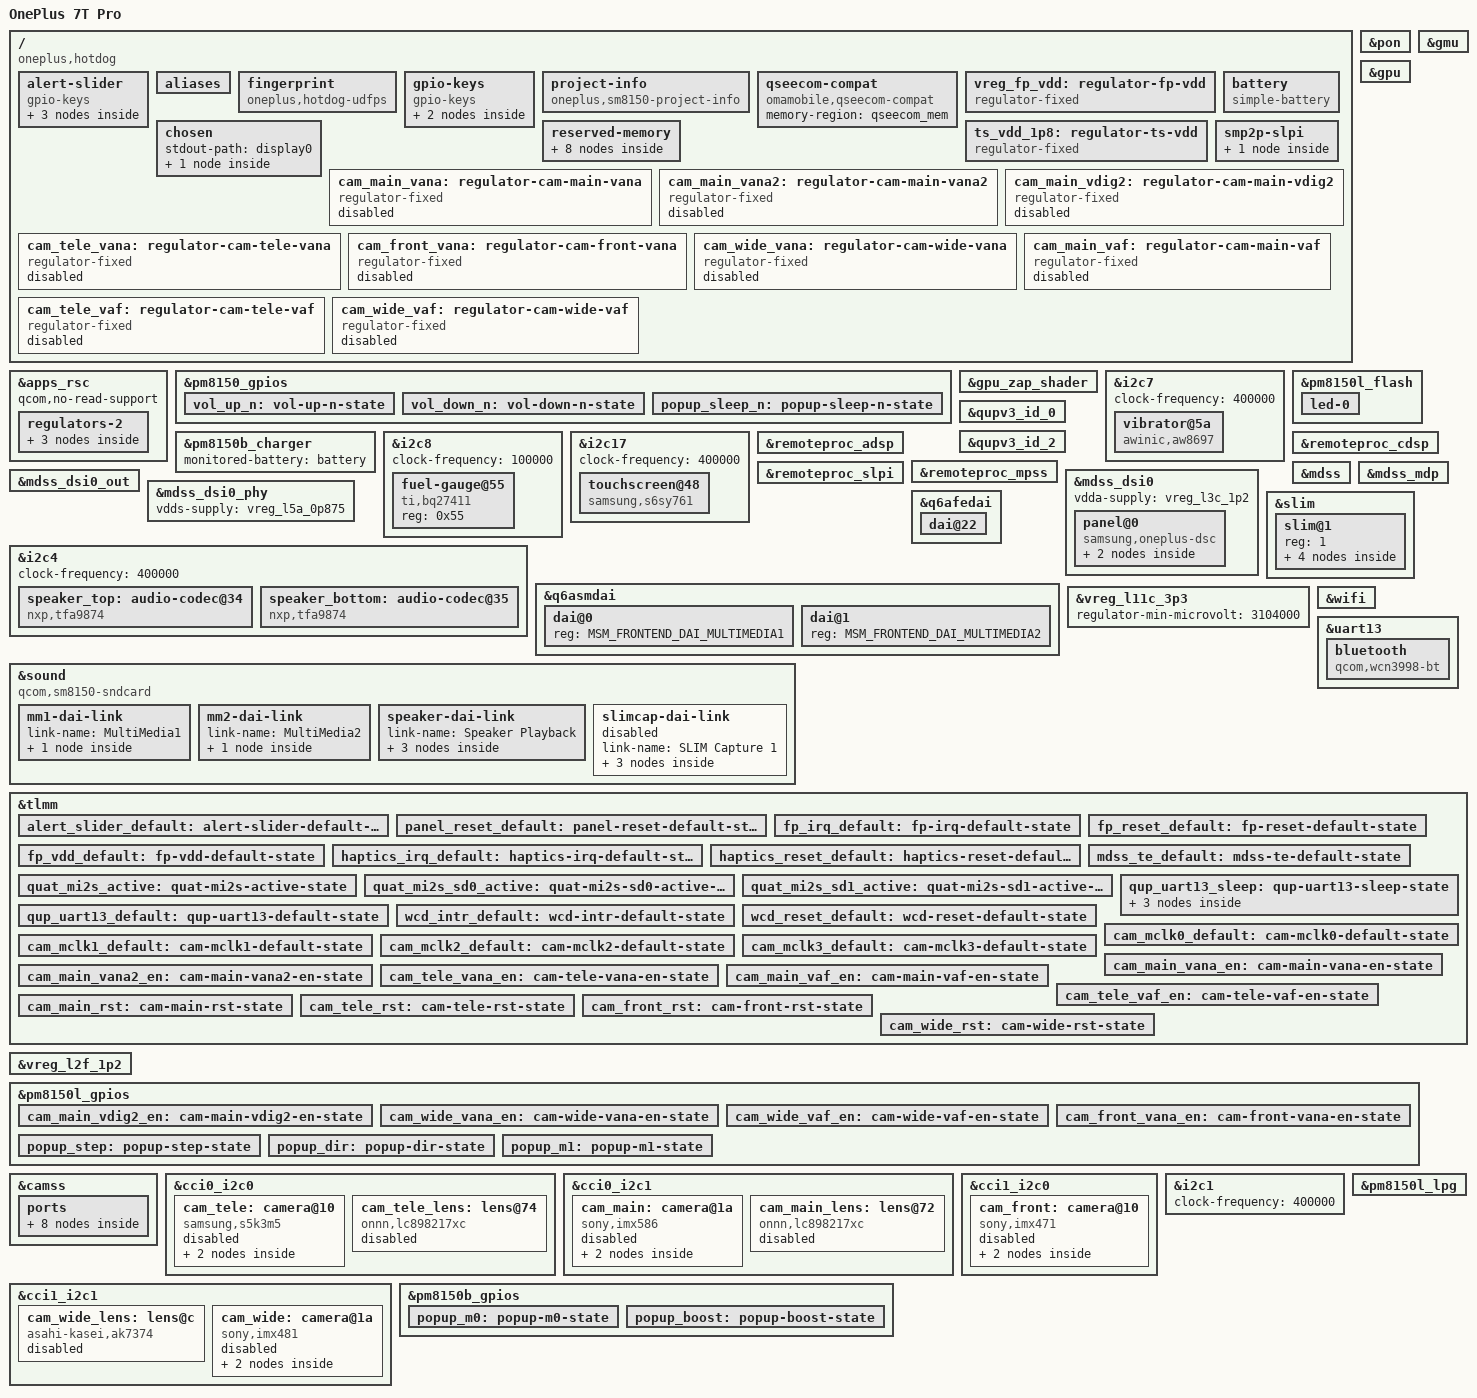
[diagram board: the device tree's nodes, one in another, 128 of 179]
// SPDX-License-Identifier: BSD-3-Clause
/*
 * Devicetree for the OnePlus 7T Pro (hotdog, project 19801).
 *
 * The board is the OnePlus 7 Pro's (guacamole): OnePlus's downstream
 * kernel builds both from the same sm8150-oem.dtsi (panel, S6SY761 touch
 * on QUP SE17, UFS, USB) and differs only in charger and battery
 * properties, which mainline doesn't describe. ABL picks the appended DTB
 * by qcom,msm-id: given a DTB without one, it answered `fastboot boot`
 * with OKAY and stayed in fastboot (Android 12 ABL). The phone's ABL
 * reports SoC 339 (SM8150); downstream also builds the board on SM8150P
 * (361), so both are listed at v2. board-id <8 0> is downstream hotdog's.
 *
 * Based on sm8150-oneplus-guacamole.dts:
 * Copyright (c) 2021, Caleb Connolly <caleb@connolly.tech>
 * Reserved regions from OnePlus's downstream sm8150.dtsi and sm8150-oem.dtsi.
 *
 * Enabled: the panel as ABL left it (simple-framebuffer), UFS, USB
 * peripheral, touch (S6SY761), the fuel gauge (BQ27411), the power and
 * volume keys and the alert slider.
 */

/dts-v1/;

#include <dt-bindings/arm/qcom,ids.h>
#include <dt-bindings/regulator/qcom,rpmh-regulator.h>
#include <dt-bindings/gpio/gpio.h>
#include <dt-bindings/interrupt-controller/irq.h>
#include <dt-bindings/leds/common.h>
#include <dt-bindings/sound/qcom,q6asm.h>
#include <dt-bindings/media/video-interfaces.h>
#include "sm8150-oneplus-common.dtsi"

/* Redone below, with guard pages, where this phone's modem expects it. */
/delete-node/ &rmtfs_mem;

/ {
	model = "OnePlus 7T Pro";
	compatible = "oneplus,hotdog", "qcom,sm8150";

	qcom,msm-id = <QCOM_ID_SM8150 0x20000>, <361 0x20000>; /* SM8150, SM8150P v2 */
	qcom,board-id = <8 0>;

	/*
	 * The three-position alert slider: one line per position, from the
	 * vendor tri-state-key node (gpio_key1 = TLMM 27, gpio_key2 = TLMM 134,
	 * gpio_key3 = TLMM 125, no internal bias). The order follows the
	 * OnePlus 6's slider in sdm845-oneplus-common.dtsi, whose vendor node
	 * lists its lines the same way (key1 bottom, key3 top). Reported as
	 * ABS_SND_PROFILE, the event the input core defines for such switches.
	 * All three lines are in the PDC's wake map, so a move wakes the phone
	 * from suspend and the new profile applies at once.
	 */
	alert-slider {
		compatible = "gpio-keys";
		label = "Alert slider";

		pinctrl-0 = <&alert_slider_default>;
		pinctrl-names = "default";

		switch-top {
			label = "Silent";
			linux,input-type = <EV_ABS>;
			linux,code = <ABS_SND_PROFILE>;
			linux,input-value = <SND_PROFILE_SILENT>;
			gpios = <&tlmm 125 GPIO_ACTIVE_LOW>;
			linux,can-disable;
			wakeup-source;
		};

		switch-middle {
			label = "Vibrate";
			linux,input-type = <EV_ABS>;
			linux,code = <ABS_SND_PROFILE>;
			linux,input-value = <SND_PROFILE_VIBRATE>;
			gpios = <&tlmm 134 GPIO_ACTIVE_LOW>;
			linux,can-disable;
			wakeup-source;
		};

		switch-bottom {
			label = "Ring";
			linux,input-type = <EV_ABS>;
			linux,code = <ABS_SND_PROFILE>;
			linux,input-value = <SND_PROFILE_RING>;
			gpios = <&tlmm 27 GPIO_ACTIVE_LOW>;
			linux,can-disable;
			wakeup-source;
		};
	};

	aliases {
		display0 = &framebuffer0;
		hsuart0 = &uart13;
	};

	/*
	 * Goodix optical sensor under the panel (stock goodix_fp node). Its SPI
	 * bus (QUP0 SE3, gpio144-147) belongs to the Goodix trusted application
	 * in QSEE; Linux drives its supply switch (gpio101), reset (gpio131) and
	 * interrupt (gpio118), and keeps the bus's pins and clocks on for QSEE,
	 * as stock's enabled qupv3_se3_spi node with no child did. spi3 itself
	 * stays disabled: Linux never drives that serial engine.
	 */
	fingerprint {
		compatible = "oneplus,hotdog-udfps";
		interrupts-extended = <&tlmm 118 IRQ_TYPE_EDGE_RISING>;
		reset-gpios = <&tlmm 131 GPIO_ACTIVE_LOW>;
		vdd-supply = <&vreg_fp_vdd>;

		clocks = <&gcc GCC_QUPV3_WRAP0_S3_CLK>,
			 <&gcc GCC_QUPV3_WRAP_0_M_AHB_CLK>,
			 <&gcc GCC_QUPV3_WRAP_0_S_AHB_CLK>;
		clock-names = "se", "m-ahb", "s-ahb";

		pinctrl-0 = <&fp_irq_default &fp_reset_default &qup_spi3_default>;
		pinctrl-names = "default";
	};

	/*
	 * The volume keys are PM8150 GPIO6 (up) and GPIO7 (down), active low with
	 * the PMIC's pull-up at the 1.8 V vin-1, as in the vendor gpio_keys node.
	 * Sampled on the phone on 2026-11-15: GPIO6 low only while Volume Up was
	 * held, GPIO7 only while Volume Down was. The vendor tree also gives
	 * PON RESIN KEY_VOLUMEDOWN; it stays disabled (as pm8150.dtsi leaves
	 * it) so one press can't report twice.
	 */
	gpio-keys {
		compatible = "gpio-keys";
		label = "Volume keys";
		autorepeat;

		pinctrl-0 = <&vol_up_n>, <&vol_down_n>;
		pinctrl-names = "default";

		key-vol-up {
			label = "Volume Up";
			linux,code = <KEY_VOLUMEUP>;
			gpios = <&pm8150_gpios 6 GPIO_ACTIVE_LOW>;
			debounce-interval = <15>;
			linux,can-disable;
			wakeup-source;
		};

		key-vol-down {
			label = "Volume Down";
			linux,code = <KEY_VOLUMEDOWN>;
			gpios = <&pm8150_gpios 7 GPIO_ACTIVE_LOW>;
			debounce-interval = <15>;
			linux,can-disable;
			wakeup-source;
		};
	};

	/* Sets the RF test cable state in SMEM for the modem (rf_v3 = no cable). */
	project-info {
		compatible = "oneplus,sm8150-project-info";
	};

	/*
	 * Downstream's /dev/qseecom for the vendor fingerprint HAL, with its
	 * shared buffers in the qseecom carve-out. Its module refuses every
	 * trusted application and listener that its allow-lists (module
	 * parameters, set by the device package) do not name.
	 */
	qseecom-compat {
		compatible = "omamobile,qseecom-compat";
		memory-region = <&qseecom_mem>;
	};

	/*
	 * The sensor's supply switch (stock fp_vdd_init / fp_vdd_dis_init). It
	 * stays off until goodix-fp's device is opened.
	 */
	vreg_fp_vdd: regulator-fp-vdd {
		compatible = "regulator-fixed";
		regulator-name = "fp_vdd";
		gpio = <&tlmm 101 GPIO_ACTIVE_HIGH>;
		enable-active-high;

		pinctrl-0 = <&fp_vdd_default>;
		pinctrl-names = "default";
	};

	/*
	 * 4085mAh typ. (gauge design capacity 4040mAh). Float voltage 4.35V,
	 * the value OnePlus's bootloader leaves in the charger (FLOAT_VOLTAGE_CFG
	 * 0x4b); downstream runs 4.365-4.39V by temperature region. The DCP
	 * input current stays below downstream's 1.8A usb-icl.
	 */
	battery: battery {
		compatible = "simple-battery";
		charge-full-design-microamp-hours = <4040000>;
		voltage-min-design-microvolt = <3400000>;
		voltage-max-design-microvolt = <4350000>;
		constant-charge-current-max-microamp = <1500000>;
	};

	chosen {
		#address-cells = <2>;
		#size-cells = <2>;
		ranges;
		stdout-path = "display0";

		/* The panel as ABL left it (cont_splash_region, 1440x3120). */
		framebuffer0: framebuffer@9c000000 {
			compatible = "simple-framebuffer";
			reg = <0 0x9c000000 0 (1440 * 3120 * 4)>;
			width = <1440>;
			height = <3120>;
			stride = <(1440 * 4)>;
			format = "a8r8g8b8";
		};
	};

	/*
	 * The touchscreen's 1.8 V: a load switch from S4A whose enable, GPIO 119,
	 * is held high by its pull-up (tp_1v8_active), as downstream leaves it.
	 */
	ts_vdd_1p8: regulator-ts-vdd {
		compatible = "regulator-fixed";
		regulator-name = "ts_vdd_1p8";
		regulator-min-microvolt = <1800000>;
		regulator-max-microvolt = <1800000>;
		regulator-always-on;
		regulator-boot-on;
		vin-supply = <&vreg_s4a_1p8>;
	};

	/*
	 * Downstream regions mainline's sm8150.dtsi leaves as System RAM.
	 * Firmware owns some of them at runtime, so keep Linux out of all.
	 */
	reserved-memory {
		/*
		 * Downstream xbl_aop_mem is 0x85e00000-0x85f40000. Mainline's
		 * xbl_mem, aop_mem and aop_cmd_db cover all of it except this gap.
		 */
		xbl_aop_gap_mem: memory@85e40000 {
			reg = <0 0x85e40000 0 0xc0000>;
			no-map;
		};

		/* The tail of downstream removed_regions, past mainline tz_mem. */
		removed_mem: memory@89b00000 {
			reg = <0 0x89b00000 0 0x1c00000>;
			no-map;
		};

		/* Downstream cont_splash_region: ABL's display buffers. */
		splash_mem: memory@9c000000 {
			reg = <0 0x9c000000 0 0x2400000>;
			no-map;
		};

		/* OnePlus's bootloader_log_mem. */
		bootloader_log_mem: memory@9fff7000 {
			reg = <0 0x9fff7000 0 0x9000>;
			no-map;
		};

		cdsp_sec_mem: memory@a4c00000 {
			reg = <0 0xa4c00000 0 0x3c00000>;
			no-map;
		};

		/*
		 * Stock's ramoops region. ramoops_probe() rounds each zone size
		 * down to a power of two and gives the dmesg records what is
		 * left, so the layout is: six 0x40000 dmesg records at +0,
		 * the console at +0x180000, pmsg at +0x1c0000 and ftrace at
		 * +0x3c0000. OnePlus's downstream kernel keeps a 0x1000
		 * devinfo zone in the same region, and its console starts
		 * 0x1000 lower (the crash-dump table names it KMSG, at
		 * 0xa997f008), so the two kernels' zones don't line up.
		 */
		ramoops@a9800000 {
			compatible = "ramoops";
			reg = <0 0xa9800000 0 0x400000>;
			record-size = <0x40000>;
			console-size = <0x40000>;
			ftrace-size = <0x40000>;
			pmsg-size = <0x200000>;
			ecc-size = <0>;
		};

		/* OnePlus's param_mem and mtp_mem. */
		param_mem: memory@ac200000 {
			reg = <0 0xac200000 0 0xc00000>;
			no-map;
		};

		/*
		 * Downstream allocates rmtfs at runtime (qcom,rmtfs_sharedmem,
		 * 2 MiB with qcom,guard-memory). On the OnePlus 7 Pro it always
		 * ends up at 0xf2901000 (sm8150-oneplus-common.dtsi). Same
		 * region here, plus the 4 KiB guard page on each side so no
		 * Linux allocation sits next to the XPU-protected range.
		 */
		rmtfs_mem: memory@f2900000 {
			compatible = "qcom,rmtfs-mem";
			reg = <0 0xf2900000 0 0x202000>;
			no-map;

			qcom,client-id = <1>;
			qcom,vmid = <QCOM_SCM_VMID_MSS_MSA>;
			qcom,use-guard-pages;
		};
	};

	/*
	 * The SLPI's sensors PD (its CHRE) takes a fatal error unless the APPS
	 * side has a "sleepstate" outbound smp2p entry, as downstream's
	 * smp2p-sleepstate driver provides. Nothing drives it yet.
	 */
	smp2p-slpi {
		sleepstate {
			qcom,entry-name = "sleepstate";
			#qcom,smem-state-cells = <1>;
		};
	};
};

/*
 * This board's apps RSC never answers an RPMh read: refuse them rather
 * than lose both active TCSes to two reads that never complete.
 */
&apps_rsc {
	qcom,no-read-support;
};

/*
 * `reboot bootloader` / `reboot recovery`: the same PON spare codes as
 * downstream's qpnp_pon_set_restart_reason() (gen2: reason << 1), which ABL reads.
 */
&pon {
	mode-bootloader = <0x2>;
	mode-recovery = <0x1>;
};

&pm8150_gpios {
	vol_up_n: vol-up-n-state {
		pins = "gpio6";
		function = "normal";
		power-source = <1>;
		bias-pull-up;
		input-enable;
	};

	vol_down_n: vol-down-n-state {
		pins = "gpio7";
		function = "normal";
		power-source = <1>;
		bias-pull-up;
		input-enable;
	};
};

&gmu {
	status = "okay";
};

&gpu {
	status = "okay";
};

/* From the phone's own vendor partition (/vendor/firmware/a640_zap.*). */
&gpu_zap_shader {
	firmware-name = "qcom/sm8150/oneplus/hotdog/a640_zap.mbn";
};

/*
 * Downstream qupv3_se7_i2c: the Awinic AW8697 LRA haptics driver (stock
 * aw8697_haptic@5A, reset on GPIO 116, interrupt on GPIO 24). The chip
 * measured the actuator at 175-176 Hz; OnePlus ships waveform sets for
 * 166 to 174 Hz.
 */
&i2c7 {
	clock-frequency = <400000>;
	status = "okay";

	vibrator@5a {
		compatible = "awinic,aw8697";
		reg = <0x5a>;
		interrupts-extended = <&tlmm 24 IRQ_TYPE_EDGE_FALLING>;
		reset-gpios = <&tlmm 116 GPIO_ACTIVE_LOW>;
		pinctrl-0 = <&haptics_irq_default &haptics_reset_default>;
		pinctrl-names = "default";
		awinic,f0-hz = <170>;
	};
};

/*
 * The rear dual-tone flash: two LEDs on the PM8150L flash module's channels
 * 1 and 2, which stock always drives together (torch_0 + torch_1 behind
 * switch_2). One torch-only LED over both, capped at stock's torch current
 * (300 mA per channel, current-ma of torch_0/torch_1; the module allows
 * 500). No flash-max-microamp: nothing here fires the flash strobe.
 * Disabled until the bring-up overlay has run (CAMERA-PLAN, T1-T2).
 */
&pm8150l_flash {
	led-0 {
		function = LED_FUNCTION_TORCH;
		color = <LED_COLOR_ID_WHITE>;
		led-sources = <1>, <2>;
		led-max-microamp = <600000>;
	};
};

/*
 * Plain USB charging (SDP 0.5A, CDP/DCP 1.5A input; fast charge current 1.95A).
 * Hardware JEITA stays as the bootloader configured it. No Warp/Dash.
 */
&pm8150b_charger {
	monitored-battery = <&battery>;
	status = "okay";
};

/* Downstream qupv3_se8_i2c: fuel gauge and OnePlus's fast-charge MCU. */
&i2c8 {
	clock-frequency = <100000>;
	status = "okay";

	/*
	 * Downstream calls it bq27541, but its driver also detects a BQ27411
	 * (device type 0x0421) and the classic bq27541 register map reads
	 * garbage on this phone.
	 */
	fuel-gauge@55 {
		compatible = "ti,bq27411";
		reg = <0x55>;
	};
};

&qupv3_id_0 {
	status = "okay";
};

&qupv3_id_2 {
	status = "okay";
};

&i2c17 {
	clock-frequency = <400000>;
	status = "okay";

	/*
	 * Downstream hotdog: 3.0 V from L17A for the analog side, 1.8 V switched
	 * by GPIO 119 (tp_1v8_active), reset GPIO 54 held by tp_rst_active.
	 */
	touchscreen@48 {
		compatible = "samsung,s6sy761";
		reg = <0x48>;
		interrupt-parent = <&tlmm>;
		interrupts = <122 IRQ_TYPE_LEVEL_LOW>;
		avdd-supply = <&vreg_l17a_3p0>;
		vdd-supply = <&ts_vdd_1p8>;

		touchscreen-size-x = <1440>;
		touchscreen-size-y = <3120>;
		samsung,ear-detect;

		pinctrl-names = "default";
		pinctrl-0 = <&tp_irq_active &tp_rst_active &tp_1v8_active>;
	};
};

/*
 * Remote processors, squashed .mbn from the phone's modem partition. A missing
 * file just leaves the remoteproc offline. The modem doesn't boot by itself
 * (auto_boot off): rmtfs starts it once it serves the EFS partitions.
 * The ELF images are relocatable and each one spans its whole region
 * (adsp 0x1e00000, modem 0x9600000, cdsp/slpi 0x1400000).
 */
&remoteproc_adsp {
	firmware-name = "qcom/sm8150/oneplus/hotdog/adsp.mbn";
	status = "okay";
};

&remoteproc_cdsp {
	firmware-name = "qcom/sm8150/oneplus/hotdog/cdsp.mbn";
	status = "okay";
};

&remoteproc_mpss {
	firmware-name = "qcom/sm8150/oneplus/hotdog/modem.mbn";
	status = "okay";
};

/*
 * The SLPI runs the sensors (Snapdragon Sensor Core: light, proximity,
 * accelerometer, compass). Its sensor_process PD reads its registry and
 * configs from Linux over FastRPC (hexagonrpcd, started by the device
 * package when /dev/fastrpc-sdsp appears); without that it stalls and its
 * watchdog restarts the SLPI about 40 s after boot.
 */
&remoteproc_slpi {
	firmware-name = "qcom/sm8150/oneplus/hotdog/slpi.mbn";
	status = "okay";
};

/*
 * Display: Samsung 1440x3120 AMOLED, command mode, DSC with two encoders on
 * one 4-lane DSI link (downstream topology <2 2 1>). Pins and supply from
 * downstream dsi_samsung_oneplus_dsc_cmd: reset GPIO 6, TE GPIO 8, vddio
 * from L14A; the other rails are switched by the panel itself.
 */
&mdss {
	status = "okay";
};

&mdss_mdp {
	status = "okay";
};

&mdss_dsi0 {
	vdda-supply = <&vreg_l3c_1p2>;
	status = "okay";

	panel@0 {
		compatible = "samsung,oneplus-dsc";
		reg = <0>;

		vddio-supply = <&vreg_l14a_1p8>;
		reset-gpios = <&tlmm 6 GPIO_ACTIVE_LOW>;

		pinctrl-names = "default";
		pinctrl-0 = <&panel_reset_default &mdss_te_default>;

		port {
			panel_in: endpoint {
				remote-endpoint = <&mdss_dsi0_out>;
			};
		};
	};
};

&mdss_dsi0_out {
	data-lanes = <0 1 2 3>;
	remote-endpoint = <&panel_in>;
};

&mdss_dsi0_phy {
	vdds-supply = <&vreg_l5a_0p875>;
	status = "okay";
};

/*
 * Speakers: two NXP TFA9874 amps on QUP SE4 I2C (downstream qupv3_se4_i2c,
 * reset GPIOs 37 and 100, active high), fed by the ADSP over quaternary MI2S
 * (SCK GPIO 137, WS 138; audio on SD1, GPIO 140, as downstream's dai_mi2s3
 * rx-lines; the amps' sense data would come back on SD0). 0x34 is the
 * earpiece at the top (the only one with a receiver profile), playing the
 * left I2S channel; 0x35 is the bottom speaker, playing the right one.
 *
 * nxp,init-bitfields replay the device and "speaker" profile settings of
 * OnePlus's tfa98xx.cnt (NXP bitfield IDs: 32-bit slots, 64 BCLK per frame,
 * slot assignment, DC-DC booster, gains). Speaker protection ran on the ADSP
 * under Android (NXP's TFADSP); it doesn't here.
 */
&i2c4 {
	clock-frequency = <400000>;
	status = "okay";

	speaker_top: audio-codec@34 {
		compatible = "nxp,tfa9874";
		reg = <0x34>;
		reset-gpios = <&tlmm 37 GPIO_ACTIVE_HIGH>;
		#sound-dai-cells = <0>;
		sound-name-prefix = "Top";
		nxp,init-bitfields = <0x20c3 2>, <0x2144 31>, <0x2224 31>, <0x2330 1>,
				     <0x2340 0>, <0x6802 3>, <0x0401 1>, <0x2310 1>,
				     <0x6163 4>, <0x6123 15>, <0x6831 1>, <0x6851 2>,
				     <0x0255 22>, <0x5257 190>, <0x5350 1>, <0x64e1 2>,
				     <0x5690 0>, <0x6f02 5>, <0x6f72 1>, <0x7071 3>,
				     <0x7430 1>, <0x7494 8>, <0x75f0 1>, <0x74f0 0>,
				     <0x8001 0>, <0x8305 25>, <0x8364 30>, <0x8453 4>,
				     <0x5150 0>, <0x5844 1>, <0x6f50 1>, <0x8510 1>,
				     <0x8530 0>, <0x8540 0>, <0x8801 2>, <0x8440 0>,
				     <0xc4d0 0>, <0xb050 0>, <0x7444 10>, <0x7534 5>,
				     <0x7584 16>, <0x7635 30>, <0x7695 63>, <0x0040 1>,
				     <0x0240 0>, <0x62e1 0>, <0x2603 0>, <0x2643 1>,
				     <0x26c3 0>, <0x2703 1>, <0x7033 11>;
	};

	speaker_bottom: audio-codec@35 {
		compatible = "nxp,tfa9874";
		reg = <0x35>;
		reset-gpios = <&tlmm 100 GPIO_ACTIVE_HIGH>;
		#sound-dai-cells = <0>;
		sound-name-prefix = "Bottom";
		nxp,init-bitfields = <0x20c3 2>, <0x2144 31>, <0x2224 31>, <0x2330 1>,
				     <0x2340 0>, <0x6802 3>, <0x0401 1>, <0x2310 1>,
				     <0x6163 4>, <0x6123 15>, <0x6831 1>, <0x6851 2>,
				     <0x0255 22>, <0x5257 190>, <0x5350 1>, <0x64e1 2>,
				     <0x5690 0>, <0x6f02 5>, <0x6f72 1>, <0x7071 3>,
				     <0x7430 1>, <0x7494 8>, <0x75f0 1>, <0x74f0 0>,
				     <0x8001 0>, <0x8305 25>, <0x8364 30>, <0x8453 4>,
				     <0x5150 0>, <0x5844 1>, <0x6f50 1>, <0x8510 1>,
				     <0x8530 0>, <0x8540 0>, <0x8801 2>, <0x8440 0>,
				     <0xc4d0 0>, <0xb050 0>, <0x7444 10>, <0x7534 5>,
				     <0x7584 16>, <0x7635 30>, <0x7695 63>, <0x0040 1>,
				     <0x0240 0>, <0x62e1 0>, <0x2603 1>, <0x2643 0>,
				     <0x26c3 1>, <0x2703 0>, <0x7033 10>;
	};
};

&q6afedai {
	dai@22 {
		reg = <QUATERNARY_MI2S_RX>;
		qcom,sd-lines = <1>;
	};
};

&q6asmdai {
	dai@0 {
		reg = <MSM_FRONTEND_DAI_MULTIMEDIA1>;
	};

	dai@1 {
		reg = <MSM_FRONTEND_DAI_MULTIMEDIA2>;
	};
};

&sound {
	compatible = "qcom,sm8150-sndcard";
	model = "OnePlus 7T Pro";
	pinctrl-names = "default";
	pinctrl-0 = <&quat_mi2s_active &quat_mi2s_sd0_active &quat_mi2s_sd1_active>;

	mm1-dai-link {
		link-name = "MultiMedia1";

		cpu {
			sound-dai = <&q6asmdai MSM_FRONTEND_DAI_MULTIMEDIA1>;
		};
	};

	mm2-dai-link {
		link-name = "MultiMedia2";

		cpu {
			sound-dai = <&q6asmdai MSM_FRONTEND_DAI_MULTIMEDIA2>;
		};
	};

	speaker-dai-link {
		link-name = "Speaker Playback";

		cpu {
			sound-dai = <&q6afedai QUATERNARY_MI2S_RX>;
		};

		platform {
			sound-dai = <&q6routing>;
		};

		codec {
			sound-dai = <&speaker_top>, <&speaker_bottom>;
		};
	};

	/*
	 * Microphones: WCD9340 AIF1_CAP on SLIMbus 0 TX. Disabled until the
	 * mic bring-up overlay (omarchy-mobile device/hotdog/overlays/mic.dtso)
	 * enables it with the SLIMbus controller and adds the card's routes:
	 * a card linked to a codec that never probes would also lose the
	 * speakers.
	 */
	slimcap-dai-link {
		link-name = "SLIM Capture 1";
		status = "disabled";

		cpu {
			sound-dai = <&q6afedai SLIMBUS_0_TX>;
		};

		platform {
			sound-dai = <&q6routing>;
		};

		codec {
			sound-dai = <&wcd9340 1>; /* AIF1_CAP */
		};
	};
};

/*
 * Microphones: a WCD9340 (Tavil) codec on SLIMbus, as OnePlus's downstream
 * sm8150 tavil_codec (stock dtbo, project 19801): reset GPIO 143, its
 * interrupt on GPIO 123, MCLK from LN_BB_CLK2 (downstream clock_audio_lnbb,
 * RPMh clock 2), 1.8 V supplies from S4A and the micbias LDO's input from
 * PM8150L BoB (downstream cdc-vdd-3v3 at 3.3 V). Micbias levels as stock:
 * 2.7 V on MICBIAS1, 2 and 4, 1.8 V on MICBIAS3. Three analog microphones
 * (stock mixer_paths_tavil.xml): AMIC4 is the voice mic ("handset-mic"),
 * AMIC3 the recording mic ("handset-mic-rec") and AMIC1 the third; AMIC2 is
 * the USB-C headset mic. The phone has no WSA speakers, so the codec's
 * SoundWire master stays off.
 *
 * The SLIMbus controller stays disabled here; the mic bring-up overlay
 * enables it.
 */
&slim {
	slim@1 {
		reg = <1>;
		#address-cells = <2>;
		#size-cells = <0>;

		wcd9340_ifd: ifd@0,0 {
			compatible = "slim217,250";
			reg = <0 0>;
		};

		wcd9340: codec@1,0 {
			compatible = "slim217,250";
			reg = <1 0>;
			slim-ifc-dev = <&wcd9340_ifd>;

			#sound-dai-cells = <1>;

			interrupts-extended = <&tlmm 123 IRQ_TYPE_LEVEL_HIGH>;
			interrupt-controller;
			#interrupt-cells = <1>;

			clock-names = "extclk";
			clocks = <&rpmhcc RPMH_LN_BB_CLK2>;

			#clock-cells = <0>;
			clock-frequency = <9600000>;
			clock-output-names = "mclk";

			pinctrl-0 = <&wcd_intr_default &wcd_reset_default>;
			pinctrl-names = "default";

			reset-gpios = <&tlmm 143 GPIO_ACTIVE_HIGH>;

			vdd-buck-supply = <&vreg_s4a_1p8>;
			vdd-buck-sido-supply = <&vreg_s4a_1p8>;
			vdd-tx-supply = <&vreg_s4a_1p8>;
			vdd-rx-supply = <&vreg_s4a_1p8>;
			vdd-io-supply = <&vreg_s4a_1p8>;
			vdd-micbias-supply = <&vreg_bob>;

			qcom,micbias1-microvolt = <2700000>;
			qcom,micbias2-microvolt = <2700000>;
			qcom,micbias3-microvolt = <1800000>;
			qcom,micbias4-microvolt = <2700000>;

			#address-cells = <1>;
			#size-cells = <1>;

			wcdgpio: gpio-controller@42 {
				compatible = "qcom,wcd9340-gpio";
				gpio-controller;
				#gpio-cells = <2>;
				reg = <0x42 0x2>;
			};

			swm: soundwire@c85 {
				compatible = "qcom,soundwire-v1.3.0";
				reg = <0xc85 0x40>;
				interrupts-extended = <&wcd9340 20>;

				qcom,dout-ports = <6>;
				qcom,din-ports = <2>;
				qcom,ports-sinterval-low =
					/bits/ 8 <0x07 0x1f 0x3f 0x07 0x1f 0x3f 0x0f 0x0f>;
				qcom,ports-offset1 =
					/bits/ 8 <0x01 0x02 0x0c 0x06 0x12 0x0d 0x07 0x0a>;
				qcom,ports-offset2 =
					/bits/ 8 <0x00 0x00 0x1f 0x00 0x00 0x1f 0x00 0x00>;

				#sound-dai-cells = <1>;
				clocks = <&wcd9340>;
				clock-names = "iface";
				#address-cells = <2>;
				#size-cells = <0>;

				status = "disabled";
			};
		};
	};
};

/*
 * WCN3990 rails from downstream's icnss node: cx-mx L1A (0.752 V), xo L7A
 * (1.8 V), rfa L2C (1.304 V), ch0 L11C (3.104-3.312 V; downstream BT asks for
 * 3.312 V on the same LDO). No ch1. MSA is wlan_mem, the same 0x180000 at
 * 0x8bc00000 as downstream's qcom,wlan-msa-fixed-region. Its firmware
 * (wlanmdsp.mbn) is loaded by the modem over tqftpserv; the board data
 * is looked up as variant oneplus_hotdog in ath10k's board-2.bin.
 */
&vreg_l11c_3p3 {
	regulator-min-microvolt = <3104000>;
};

&wifi {
	vdd-0.8-cx-mx-supply = <&vreg_l1a_0p75>;
	vdd-1.8-xo-supply = <&vreg_l7a_1p8>;
	vdd-1.3-rfa-supply = <&vreg_l2c_1p3>;
	vdd-3.3-ch0-supply = <&vreg_l11c_3p3>;

	qcom,calibration-variant = "oneplus_hotdog";

	status = "okay";
};

/*
 * WCN3990 Bluetooth on QUP SE13 as a 4-wire UART (downstream
 * qupv3_se13_4uart, wake IRQ on RX GPIO 46), powered from the same rails as
 * Wi-Fi. Firmware is stock's bluetooth_a image: crbtfw21.tlv and the NVM
 * picked by board ID (crnv21.bXX, else crnv21.bin), as Android does.
 */
&uart13 {
	/delete-property/ interrupts;
	interrupts-extended = <&intc GIC_SPI 585 IRQ_TYPE_LEVEL_HIGH>,
			      <&tlmm 46 IRQ_TYPE_EDGE_FALLING>;

	pinctrl-names = "default", "sleep";
	pinctrl-0 = <&qup_uart13_default>;
	pinctrl-1 = <&qup_uart13_sleep>;

	status = "okay";

	bluetooth: bluetooth {
		compatible = "qcom,wcn3998-bt";
		vddio-supply = <&vreg_l1a_0p75>;
		vddxo-supply = <&vreg_l7a_1p8>;
		vddrf-supply = <&vreg_l2c_1p3>;
		vddch0-supply = <&vreg_l11c_3p3>;
		max-speed = <3200000>;
		firmware-name = "crnv21", "crbtfw21.tlv";
	};
};

&tlmm {
	alert_slider_default: alert-slider-default-state {
		pins = "gpio27", "gpio125", "gpio134";
		function = "gpio";
		drive-strength = <2>;
		bias-disable;
	};

	panel_reset_default: panel-reset-default-state {
		pins = "gpio6";
		function = "gpio";
		drive-strength = <8>;
		bias-disable;
	};

	/* Fingerprint pins as stock's fp_irq_init, fp_reset_init, fp_vdd_*. */
	fp_irq_default: fp-irq-default-state {
		pins = "gpio118";
		function = "gpio";
		drive-strength = <2>;
		bias-disable;
		output-disable;
	};

	fp_reset_default: fp-reset-default-state {
		pins = "gpio131";
		function = "gpio";
		drive-strength = <8>;
		bias-pull-up;
	};

	/* Stock pulls down while off; the regulator drives it while on. */
	fp_vdd_default: fp-vdd-default-state {
		pins = "gpio101";
		function = "gpio";
		drive-strength = <8>;
		bias-pull-down;
	};

	/* Haptics pins as stock's aw_irq and aw_reset (whose names are swapped). */
	haptics_irq_default: haptics-irq-default-state {
		pins = "gpio24";
		function = "gpio";
		drive-strength = <2>;
		bias-disable;
		output-disable;
	};

	haptics_reset_default: haptics-reset-default-state {
		pins = "gpio116";
		function = "gpio";
		drive-strength = <2>;
		bias-disable;
	};

	mdss_te_default: mdss-te-default-state {
		pins = "gpio8";
		function = "mdp_vsync";
		drive-strength = <2>;
		bias-pull-down;
	};

	/* Pin settings from downstream's quat_mi2s*_active states. */
	quat_mi2s_active: quat-mi2s-active-state {
		pins = "gpio137", "gpio138";
		function = "qua_mi2s";
		drive-strength = <8>;
		bias-disable;
		output-high;
	};

	quat_mi2s_sd0_active: quat-mi2s-sd0-active-state {
		pins = "gpio139";
		function = "qua_mi2s";
		drive-strength = <8>;
		bias-disable;
	};

	quat_mi2s_sd1_active: quat-mi2s-sd1-active-state {
		pins = "gpio140";
		function = "qua_mi2s";
		drive-strength = <8>;
		bias-disable;
	};

	qup_uart13_default: qup-uart13-default-state {
		pins = "gpio43", "gpio44", "gpio45", "gpio46";
		function = "qup13";
		drive-strength = <2>;
		bias-disable;
	};

	/* Pulls from downstream's qupv3_se13 sleep states. */
	qup_uart13_sleep: qup-uart13-sleep-state {
		pinmux {
			pins = "gpio43", "gpio44", "gpio45", "gpio46";
			function = "gpio";
		};

		pinconf-cts-rts {
			pins = "gpio43", "gpio44";
			bias-pull-down;
		};

		pinconf-tx-rx {
			pins = "gpio45", "gpio46";
			bias-pull-up;
		};
	};

	/* Stock's wcd_intr_default. */
	wcd_intr_default: wcd-intr-default-state {
		pins = "gpio123";
		function = "gpio";
		drive-strength = <2>;
		bias-pull-down;
	};

	/* Stock's cdc_reset_active; the driver drives the level. */
	wcd_reset_default: wcd-reset-default-state {
		pins = "gpio143";
		function = "gpio";
		drive-strength = <8>;
		bias-pull-down;
	};
};

/*
 * Cameras (CAMERA-PLAN.md). Everything below stays disabled; the plan's
 * overlays enable it one step at a time. Wiring from the vendor device tree
 * (dtbo entry 18, "MTP 19801", OnePlus's fragment on cam_cci0) and the
 * camera module files of OxygenOS 10.0.14:
 *
 *   camera     sensor  CCI     addr  CSIPHY          MCLK          XCLR
 *   rear main  IMX586  0 / m1  0x1a  1, C-PHY 3 trio 1, 19.2 MHz  gpio30
 *   telephoto  S5K3M5  0 / m0  0x10  0, D-PHY 4 lane 0, 24 MHz *  gpio28
 *   front      IMX471  1 / m0  0x10  2, D-PHY 4 lane 2, 19.2 MHz  gpio12
 *   ultrawide  IMX481  1 / m1  0x1a  3, D-PHY 4 lane 3, 19.2 MHz  gpio23
 *
 *   main:  vana gpio11, vana2 gpio29, vdig L1F 1.104 V, vdig2 PM8150L gpio1
 *   tele:  vana gpio148, vdig L2F 1.056 V
 *   front: vana PM8150L gpio12, vdig L3F 1.056 V
 *   wide:  vana PM8150L gpio2, vdig L4F 1.056 V
 *
 * All share vio (L1C, 1.8 V). The vana and vana2/vdig2 rails are load
 * switches the vendor tree drives as GPIOs, fed from BoB; their output
 * voltage is not described anywhere we can read. Stock runs the S5K3M5 at
 * 19.2 MHz; the mainline driver's tables are written for 24 MHz (*), which
 * the camera clock controller gives exactly. The OIS controllers and EEPROMs
 * are left out.
 *
 * Focus actuators (voice coils), from the same sources: each has its own
 * load switch from BoB (vendor "cam_vaf", 3.3 V), on gpio25 (main), gpio35
 * (tele) and PM8150L gpio4 (wide). Main and tele are one dual module, and
 * which chips it has depends on its maker: SEMCO's has LC898217XCs at 0x72
 * (main) and 0x74 (tele), O-film's AK7374s at 0x2d and 0x74. The nodes
 * below describe the SEMCO module; for an O-film one, the main lens is an
 * asahi-kasei,ak7374 at 0x2d and the tele lens an asahi-kasei,ak7374 at
 * 0x74. The ultrawide has an AK7374 at 0x0c either way. All three take
 * 10-bit positions. The lenses stay disabled, so the sensors' lens-focus
 * links are ignored, until a bring-up overlay enables them with their
 * switches.
 * Rotation is the vendor's sensor-position-roll; orientation its yaw.
 */
/ {
	cam_main_vana: regulator-cam-main-vana {
		compatible = "regulator-fixed";
		regulator-name = "cam_main_vana";
		gpio = <&tlmm 11 GPIO_ACTIVE_HIGH>;
		enable-active-high;
		vin-supply = <&vreg_bob>;
		pinctrl-0 = <&cam_main_vana_en>;
		pinctrl-names = "default";
		status = "disabled";
	};

	cam_main_vana2: regulator-cam-main-vana2 {
		compatible = "regulator-fixed";
		regulator-name = "cam_main_vana2";
		gpio = <&tlmm 29 GPIO_ACTIVE_HIGH>;
		enable-active-high;
		vin-supply = <&vreg_bob>;
		pinctrl-0 = <&cam_main_vana2_en>;
		pinctrl-names = "default";
		status = "disabled";
	};

	cam_main_vdig2: regulator-cam-main-vdig2 {
		compatible = "regulator-fixed";
		regulator-name = "cam_main_vdig2";
		gpio = <&pm8150l_gpios 1 GPIO_ACTIVE_HIGH>;
		enable-active-high;
		vin-supply = <&vreg_bob>;
		pinctrl-0 = <&cam_main_vdig2_en>;
		pinctrl-names = "default";
		status = "disabled";
	};

	cam_tele_vana: regulator-cam-tele-vana {
		compatible = "regulator-fixed";
		regulator-name = "cam_tele_vana";
		gpio = <&tlmm 148 GPIO_ACTIVE_HIGH>;
		enable-active-high;
		vin-supply = <&vreg_bob>;
		pinctrl-0 = <&cam_tele_vana_en>;
		pinctrl-names = "default";
		status = "disabled";
	};

	cam_front_vana: regulator-cam-front-vana {
		compatible = "regulator-fixed";
		regulator-name = "cam_front_vana";
		gpio = <&pm8150l_gpios 12 GPIO_ACTIVE_HIGH>;
		enable-active-high;
		vin-supply = <&vreg_bob>;
		pinctrl-0 = <&cam_front_vana_en>;
		pinctrl-names = "default";
		status = "disabled";
	};

	cam_wide_vana: regulator-cam-wide-vana {
		compatible = "regulator-fixed";
		regulator-name = "cam_wide_vana";
		gpio = <&pm8150l_gpios 2 GPIO_ACTIVE_HIGH>;
		enable-active-high;
		vin-supply = <&vreg_bob>;
		pinctrl-0 = <&cam_wide_vana_en>;
		pinctrl-names = "default";
		status = "disabled";
	};

	cam_main_vaf: regulator-cam-main-vaf {
		compatible = "regulator-fixed";
		regulator-name = "cam_main_vaf";
		gpio = <&tlmm 25 GPIO_ACTIVE_HIGH>;
		enable-active-high;
		vin-supply = <&vreg_bob>;
		pinctrl-0 = <&cam_main_vaf_en>;
		pinctrl-names = "default";
		status = "disabled";
	};

	cam_tele_vaf: regulator-cam-tele-vaf {
		compatible = "regulator-fixed";
		regulator-name = "cam_tele_vaf";
		gpio = <&tlmm 35 GPIO_ACTIVE_HIGH>;
		enable-active-high;
		vin-supply = <&vreg_bob>;
		pinctrl-0 = <&cam_tele_vaf_en>;
		pinctrl-names = "default";
		status = "disabled";
	};

	cam_wide_vaf: regulator-cam-wide-vaf {
		compatible = "regulator-fixed";
		regulator-name = "cam_wide_vaf";
		gpio = <&pm8150l_gpios 4 GPIO_ACTIVE_HIGH>;
		enable-active-high;
		vin-supply = <&vreg_bob>;
		pinctrl-0 = <&cam_wide_vaf_en>;
		pinctrl-names = "default";
		status = "disabled";
	};
};

&apps_rsc {
	regulators-2 {
		vreg_l1f_1p104: ldo1 {
			regulator-min-microvolt = <1104000>;
			regulator-max-microvolt = <1104000>;
			regulator-initial-mode = <RPMH_REGULATOR_MODE_HPM>;
		};

		vreg_l3f_1p056: ldo3 {
			regulator-min-microvolt = <1056000>;
			regulator-max-microvolt = <1056000>;
			regulator-initial-mode = <RPMH_REGULATOR_MODE_HPM>;
		};

		vreg_l4f_1p056: ldo4 {
			regulator-min-microvolt = <1056000>;
			regulator-max-microvolt = <1056000>;
			regulator-initial-mode = <RPMH_REGULATOR_MODE_HPM>;
		};
	};
};

/* The telephoto's digital core: 1.056 V on this board, not the MTP's 1.2 V. */
&vreg_l2f_1p2 {
	regulator-min-microvolt = <1056000>;
	regulator-max-microvolt = <1056000>;
};

&pm8150l_gpios {
	cam_main_vdig2_en: cam-main-vdig2-en-state {
		pins = "gpio1";
		function = "normal";
		power-source = <0>;
		bias-disable;
		output-low;
	};

	cam_wide_vana_en: cam-wide-vana-en-state {
		pins = "gpio2";
		function = "normal";
		power-source = <0>;
		bias-disable;
		output-low;
	};

	cam_wide_vaf_en: cam-wide-vaf-en-state {
		pins = "gpio4";
		function = "normal";
		power-source = <0>;
		bias-disable;
		output-low;
	};

	cam_front_vana_en: cam-front-vana-en-state {
		pins = "gpio12";
		function = "normal";
		power-source = <0>;
		bias-disable;
		output-low;
	};
};

&tlmm {
	cam_mclk0_default: cam-mclk0-default-state {
		pins = "gpio13";
		function = "cam_mclk";
		drive-strength = <2>;
		bias-disable;
	};

	cam_mclk1_default: cam-mclk1-default-state {
		pins = "gpio14";
		function = "cam_mclk";
		drive-strength = <2>;
		bias-disable;
	};

	cam_mclk2_default: cam-mclk2-default-state {
		pins = "gpio15";
		function = "cam_mclk";
		drive-strength = <2>;
		bias-disable;
	};

	cam_mclk3_default: cam-mclk3-default-state {
		pins = "gpio16";
		function = "cam_mclk";
		drive-strength = <2>;
		bias-disable;
	};

	cam_main_vana_en: cam-main-vana-en-state {
		pins = "gpio11";
		function = "gpio";
		drive-strength = <2>;
		bias-disable;
	};

	cam_main_vana2_en: cam-main-vana2-en-state {
		pins = "gpio29";
		function = "gpio";
		drive-strength = <2>;
		bias-disable;
	};

	cam_tele_vana_en: cam-tele-vana-en-state {
		pins = "gpio148";
		function = "gpio";
		drive-strength = <2>;
		bias-disable;
	};

	cam_main_vaf_en: cam-main-vaf-en-state {
		pins = "gpio25";
		function = "gpio";
		drive-strength = <2>;
		bias-disable;
	};

	cam_tele_vaf_en: cam-tele-vaf-en-state {
		pins = "gpio35";
		function = "gpio";
		drive-strength = <2>;
		bias-disable;
	};

	cam_main_rst: cam-main-rst-state {
		pins = "gpio30";
		function = "gpio";
		drive-strength = <2>;
		bias-disable;
	};

	cam_tele_rst: cam-tele-rst-state {
		pins = "gpio28";
		function = "gpio";
		drive-strength = <2>;
		bias-disable;
	};

	cam_front_rst: cam-front-rst-state {
		pins = "gpio12";
		function = "gpio";
		drive-strength = <2>;
		bias-disable;
	};

	cam_wide_rst: cam-wide-rst-state {
		pins = "gpio23";
		function = "gpio";
		drive-strength = <2>;
		bias-disable;
	};
};

&camss {
	vdda-phy-supply = <&vreg_l5a_0p875>;
	vdda-pll-supply = <&vreg_l3c_1p2>;

	ports {
		port@0 {
			camss_csiphy0_ep: endpoint {
				clock-lanes = <7>;
				data-lanes = <0 1 2 3>;
				remote-endpoint = <&cam_tele_ep>;
			};
		};

		port@1 {
			camss_csiphy1_ep: endpoint {
				bus-type = <MEDIA_BUS_TYPE_CSI2_CPHY>;
				clock-lanes = <7>;
				data-lanes = <0 1 2>;
				remote-endpoint = <&cam_main_ep>;
			};
		};

		port@2 {
			camss_csiphy2_ep: endpoint {
				clock-lanes = <7>;
				data-lanes = <0 1 2 3>;
				remote-endpoint = <&cam_front_ep>;
			};
		};

		port@3 {
			camss_csiphy3_ep: endpoint {
				clock-lanes = <7>;
				data-lanes = <0 1 2 3>;
				remote-endpoint = <&cam_wide_ep>;
			};
		};
	};
};

&cci0_i2c0 {
	cam_tele: camera@10 {
		compatible = "samsung,s5k3m5";
		reg = <0x10>;
		clocks = <&camcc CAM_CC_MCLK0_CLK>;
		assigned-clocks = <&camcc CAM_CC_MCLK0_CLK>;
		assigned-clock-rates = <24000000>;
		reset-gpios = <&tlmm 28 GPIO_ACTIVE_LOW>;
		vdda-supply = <&cam_tele_vana>;
		vddd-supply = <&vreg_l2f_1p2>;
		vddio-supply = <&vreg_l1c_1p8>;
		pinctrl-0 = <&cam_mclk0_default>, <&cam_tele_rst>;
		pinctrl-names = "default";
		lens-focus = <&cam_tele_lens>;
		orientation = <1>;
		rotation = <90>;
		status = "disabled";

		port {
			cam_tele_ep: endpoint {
				data-lanes = <1 2 3 4>;
				link-frequencies = /bits/ 64 <602500000>;
				remote-endpoint = <&camss_csiphy0_ep>;
			};
		};
	};

	cam_tele_lens: lens@74 {
		compatible = "onnn,lc898217xc";
		reg = <0x74>;
		vdd-supply = <&cam_tele_vaf>;
		vio-supply = <&vreg_l1c_1p8>;
		status = "disabled";
	};
};

&cci0_i2c1 {
	cam_main: camera@1a {
		compatible = "sony,imx586";
		reg = <0x1a>;
		firmware-name = "omamobile/camera/imx586-main.bin";
		clocks = <&camcc CAM_CC_MCLK1_CLK>;
		assigned-clocks = <&camcc CAM_CC_MCLK1_CLK>;
		assigned-clock-rates = <19200000>;
		reset-gpios = <&tlmm 30 GPIO_ACTIVE_LOW>;
		vana-supply = <&cam_main_vana>;
		vana2-supply = <&cam_main_vana2>;
		vdig-supply = <&vreg_l1f_1p104>;
		vdig2-supply = <&cam_main_vdig2>;
		vif-supply = <&vreg_l1c_1p8>;
		pinctrl-0 = <&cam_mclk1_default>, <&cam_main_rst>;
		pinctrl-names = "default";
		lens-focus = <&cam_main_lens>;
		orientation = <1>;
		rotation = <90>;
		status = "disabled";

		port {
			cam_main_ep: endpoint {
				bus-type = <MEDIA_BUS_TYPE_CSI2_CPHY>;
				data-lanes = <1 2 3>;
				link-frequencies = /bits/ 64 <421203125 340003125>;
				remote-endpoint = <&camss_csiphy1_ep>;
			};
		};
	};

	cam_main_lens: lens@72 {
		compatible = "onnn,lc898217xc";
		reg = <0x72>;
		vdd-supply = <&cam_main_vaf>;
		vio-supply = <&vreg_l1c_1p8>;
		status = "disabled";
	};
};

&cci1_i2c0 {
	cam_front: camera@10 {
		compatible = "sony,imx471";
		reg = <0x10>;
		clocks = <&camcc CAM_CC_MCLK2_CLK>;
		assigned-clocks = <&camcc CAM_CC_MCLK2_CLK>;
		assigned-clock-rates = <19200000>;
		reset-gpios = <&tlmm 12 GPIO_ACTIVE_LOW>;
		vana-supply = <&cam_front_vana>;
		vdig-supply = <&vreg_l3f_1p056>;
		vif-supply = <&vreg_l1c_1p8>;
		pinctrl-0 = <&cam_mclk2_default>, <&cam_front_rst>;
		pinctrl-names = "default";
		orientation = <0>;
		rotation = <90>;
		status = "disabled";

		port {
			cam_front_ep: endpoint {
				data-lanes = <1 2 3 4>;
				link-frequencies = /bits/ 64 <200000000>;
				remote-endpoint = <&camss_csiphy2_ep>;
			};
		};
	};
};

&cci1_i2c1 {
	cam_wide_lens: lens@c {
		compatible = "asahi-kasei,ak7374";
		reg = <0x0c>;
		vdd-supply = <&cam_wide_vaf>;
		vio-supply = <&vreg_l1c_1p8>;
		status = "disabled";
	};

	cam_wide: camera@1a {
		compatible = "sony,imx481";
		reg = <0x1a>;
		firmware-name = "omamobile/camera/imx481-wide.bin";
		clocks = <&camcc CAM_CC_MCLK3_CLK>;
		assigned-clocks = <&camcc CAM_CC_MCLK3_CLK>;
		assigned-clock-rates = <19200000>;
		reset-gpios = <&tlmm 23 GPIO_ACTIVE_LOW>;
		vana-supply = <&cam_wide_vana>;
		vdig-supply = <&vreg_l4f_1p056>;
		vif-supply = <&vreg_l1c_1p8>;
		pinctrl-0 = <&cam_mclk3_default>, <&cam_wide_rst>;
		pinctrl-names = "default";
		lens-focus = <&cam_wide_lens>;
		orientation = <1>;
		/*
		 * Stock describes this module as roll 270, yaw 0 and the other
		 * rear ones as roll 90, yaw 180: the same mounting, seen from
		 * the other side. The captured picture matches the other rear
		 * cameras.
		 */
		rotation = <90>;
		status = "disabled";

		port {
			cam_wide_ep: endpoint {
				data-lanes = <1 2 3 4>;
				link-frequencies = /bits/ 64 <659200000>;
				remote-endpoint = <&camss_csiphy3_ep>;
			};
		};
	};
};

/*
 * The front camera's pop-up (CAMERA-PLAN.md, P-steps): a DRV8834 stepper
 * driver in 1/32-step mode and two MagnaChip M1120 hall sensors, from the
 * vendor device tree and OnePlus's GPL motor driver. STEP is PM8150L
 * GPIO10 in its PWM function (the LPG channel at 0xbd00); DIR (PM8150L
 * GPIO11), M1 (PM8150L GPIO8), nSLEEP (PM8150 GPIO10) and the boost enable
 * (PM8150B GPIO12) are plain outputs; M0 (PM8150B GPIO5) floats, which with
 * M1 high selects 1/32 steps. The LPG carries all their pin states, so
 * nothing changes on these pins until the LPG is enabled; omamobile-hotdog-
 * popup drives the motor from userspace. The hall sensors (0x0c at the top,
 * 0x0d at the bottom; vdd L7C, vio L8C) sit on QUP SE1 with no kernel
 * driver: the same tool reads them through i2c-dev.
 */
&i2c1 {
	clock-frequency = <400000>;
};

&pm8150l_lpg {
	pinctrl-0 = <&popup_step>, <&popup_dir>, <&popup_m1>,
		    <&popup_sleep_n>, <&popup_m0>, <&popup_boost>;
	pinctrl-names = "default";
};

&pm8150_gpios {
	popup_sleep_n: popup-sleep-n-state {
		pins = "gpio10";
		function = "normal";
		power-source = <0>;
		bias-disable;
		output-low;
	};
};

&pm8150b_gpios {
	popup_m0: popup-m0-state {
		pins = "gpio5";
		function = "normal";
		bias-high-impedance;
	};

	popup_boost: popup-boost-state {
		pins = "gpio12";
		function = "normal";
		bias-disable;
		output-low;
	};
};

&pm8150l_gpios {
	popup_step: popup-step-state {
		pins = "gpio10";
		function = "func1";
		power-source = <0>;
		bias-disable;
		output-low;
		drive-push-pull;
		qcom,drive-strength = <3>;
	};

	popup_dir: popup-dir-state {
		pins = "gpio11";
		function = "normal";
		power-source = <0>;
		bias-disable;
		output-low;
		qcom,drive-strength = <3>;
	};

	popup_m1: popup-m1-state {
		pins = "gpio8";
		function = "normal";
		power-source = <0>;
		bias-disable;
		output-low;
		qcom,drive-strength = <3>;
	};
};
